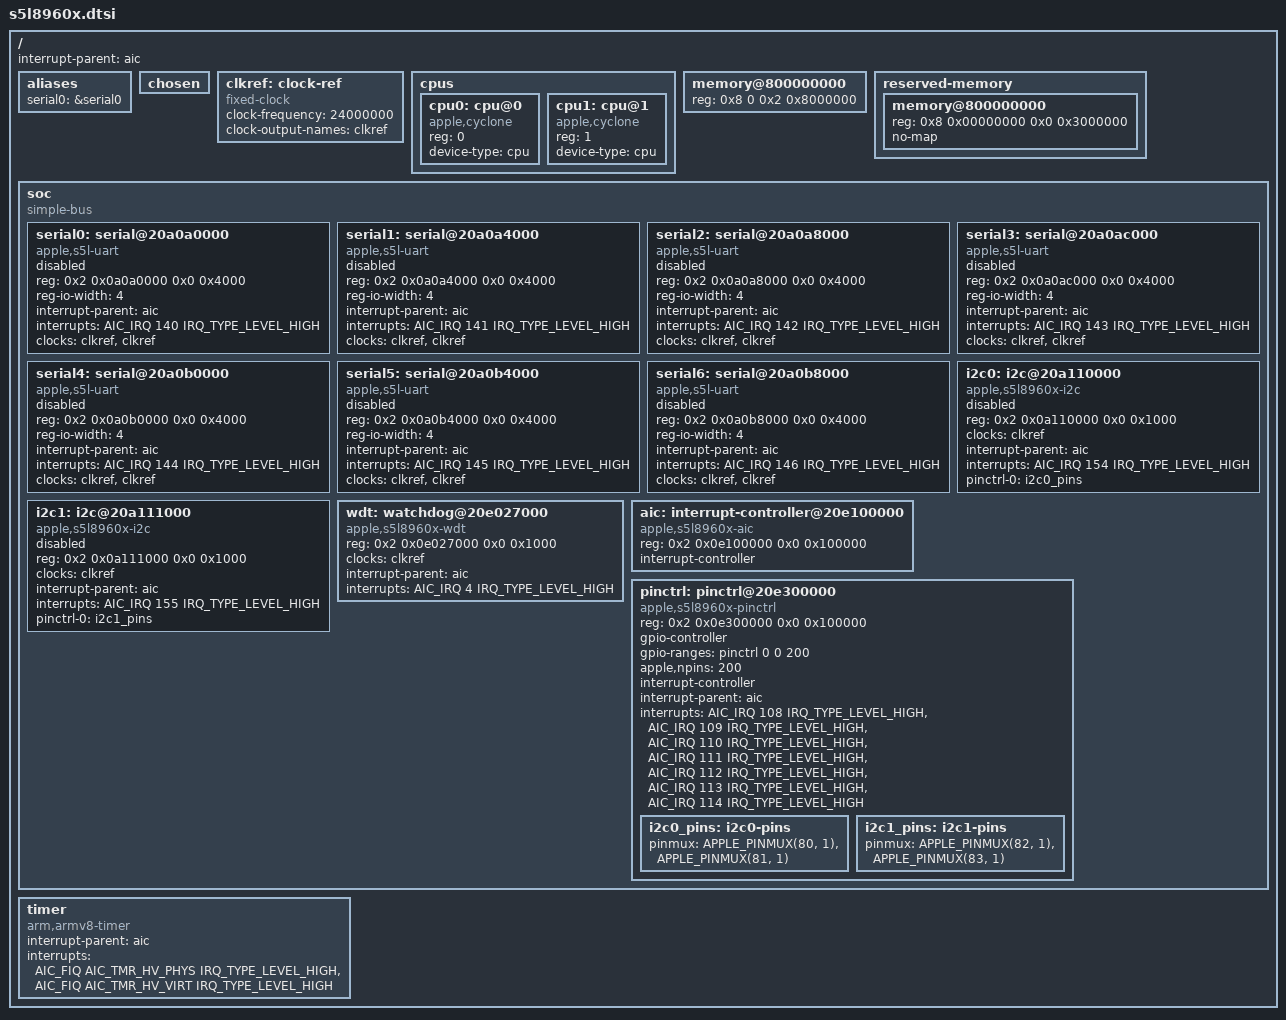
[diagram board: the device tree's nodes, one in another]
// SPDX-License-Identifier: GPL-2.0+ OR MIT
/*
 * Apple S5L8960X "A7" SoC
 *
 * Copyright (c) 2022, Konrad Dybcio <konrad.dybcio@somainline.org>
 * Based on Asahi Linux's M1 (t8103.dtsi) and Corellium's A10 efforts.
 */

#include <dt-bindings/gpio/gpio.h>
#include <dt-bindings/interrupt-controller/apple-aic.h>
#include <dt-bindings/interrupt-controller/irq.h>
#include <dt-bindings/pinctrl/apple.h>

/ {
	interrupt-parent = <&aic>;
	#address-cells = <2>;
	#size-cells = <2>;

	aliases {
		serial0 = &serial0;
	};

	chosen {
		#address-cells = <2>;
		#size-cells = <2>;
		ranges;
	};

	clkref: clock-ref {
		compatible = "fixed-clock";
		#clock-cells = <0>;
		clock-frequency = <24000000>;
		clock-output-names = "clkref";
	};

	cpus {
		#address-cells = <1>;
		#size-cells = <0>;

		cpu0: cpu@0 {
			compatible = "apple,cyclone";
			reg = <0>;
			device-type = "cpu";
		};

		cpu1: cpu@1 {
			compatible = "apple,cyclone";
			reg = <1>;
			device-type = "cpu";
		};
	};

	memory@800000000 {
		device_type = "memory";
		reg = <0x8 0 0x2 0x8000000>; /* To be filled by loader */
	};

	reserved-memory {
		#address-cells = <2>;
		#size-cells = <2>;
		ranges;

		memory@800000000 {
			reg = <0x8 0x00000000 0x0 0x3000000>;
			no-map;
		};
	};

	soc {
		compatible = "simple-bus";
		#address-cells = <2>;
		#size-cells = <2>;
		ranges;

		serial0: serial@20a0a0000 {
			compatible = "apple,s5l-uart";
			reg = <0x2 0x0a0a0000 0x0 0x4000>;
			reg-io-width = <4>;
			interrupt-parent = <&aic>;
			interrupts = <AIC_IRQ 140 IRQ_TYPE_LEVEL_HIGH>;
			/* Use the bootloader-enabled clocks for now. */
			clocks = <&clkref>, <&clkref>;
			clock-names = "uart", "clk_uart_baud0";
			status = "disabled";
		};

		serial1: serial@20a0a4000 {
			compatible = "apple,s5l-uart";
			reg = <0x2 0x0a0a4000 0x0 0x4000>;
			reg-io-width = <4>;
			interrupt-parent = <&aic>;
			interrupts = <AIC_IRQ 141 IRQ_TYPE_LEVEL_HIGH>;
			/* Use the bootloader-enabled clocks for now. */
			clocks = <&clkref>, <&clkref>;
			clock-names = "uart", "clk_uart_baud0";
			status = "disabled";
		};

		serial2: serial@20a0a8000 {
			compatible = "apple,s5l-uart";
			reg = <0x2 0x0a0a8000 0x0 0x4000>;
			reg-io-width = <4>;
			interrupt-parent = <&aic>;
			interrupts = <AIC_IRQ 142 IRQ_TYPE_LEVEL_HIGH>;
			/* Use the bootloader-enabled clocks for now. */
			clocks = <&clkref>, <&clkref>;
			clock-names = "uart", "clk_uart_baud0";
			status = "disabled";
		};

		serial3: serial@20a0ac000 {
			compatible = "apple,s5l-uart";
			reg = <0x2 0x0a0ac000 0x0 0x4000>;
			reg-io-width = <4>;
			interrupt-parent = <&aic>;
			interrupts = <AIC_IRQ 143 IRQ_TYPE_LEVEL_HIGH>;
			/* Use the bootloader-enabled clocks for now. */
			clocks = <&clkref>, <&clkref>;
			clock-names = "uart", "clk_uart_baud0";
			status = "disabled";
		};

		serial4: serial@20a0b0000 {
			compatible = "apple,s5l-uart";
			reg = <0x2 0x0a0b0000 0x0 0x4000>;
			reg-io-width = <4>;
			interrupt-parent = <&aic>;
			interrupts = <AIC_IRQ 144 IRQ_TYPE_LEVEL_HIGH>;
			/* Use the bootloader-enabled clocks for now. */
			clocks = <&clkref>, <&clkref>;
			clock-names = "uart", "clk_uart_baud0";
			status = "disabled";
		};

		serial5: serial@20a0b4000 {
			compatible = "apple,s5l-uart";
			reg = <0x2 0x0a0b4000 0x0 0x4000>;
			reg-io-width = <4>;
			interrupt-parent = <&aic>;
			interrupts = <AIC_IRQ 145 IRQ_TYPE_LEVEL_HIGH>;
			/* Use the bootloader-enabled clocks for now. */
			clocks = <&clkref>, <&clkref>;
			clock-names = "uart", "clk_uart_baud0";
			status = "disabled";
		};

		serial6: serial@20a0b8000 {
			compatible = "apple,s5l-uart";
			reg = <0x2 0x0a0b8000 0x0 0x4000>;
			reg-io-width = <4>;
			interrupt-parent = <&aic>;
			interrupts = <AIC_IRQ 146 IRQ_TYPE_LEVEL_HIGH>;
			/* Use the bootloader-enabled clocks for now. */
			clocks = <&clkref>, <&clkref>;
			clock-names = "uart", "clk_uart_baud0";
			status = "disabled";
		};

		i2c0: i2c@20a110000 {
			compatible = "apple,s5l8960x-i2c", "apple,i2c";
			reg = <0x2 0x0a110000 0x0 0x1000>;
			clocks = <&clkref>;
			interrupt-parent = <&aic>;
			interrupts = <AIC_IRQ 154 IRQ_TYPE_LEVEL_HIGH>;
			pinctrl-0 = <&i2c0_pins>;
			pinctrl-names = "default";
			#address-cells = <1>;
			#size-cells = <0>;
			status = "disabled";
		};

		i2c1: i2c@20a111000 {
			compatible = "apple,s5l8960x-i2c", "apple,i2c";
			reg = <0x2 0x0a111000 0x0 0x1000>;
			clocks = <&clkref>;
			interrupt-parent = <&aic>;
			interrupts = <AIC_IRQ 155 IRQ_TYPE_LEVEL_HIGH>;
			pinctrl-0 = <&i2c1_pins>;
			pinctrl-names = "default";
			#address-cells = <1>;
			#size-cells = <0>;
			status = "disabled";
		};

		wdt: watchdog@20e027000 {
			compatible = "apple,s5l8960x-wdt", "apple,wdt";
			reg = <0x2 0x0e027000 0x0 0x1000>;
			clocks = <&clkref>;
			interrupt-parent = <&aic>;
			interrupts = <AIC_IRQ 4 IRQ_TYPE_LEVEL_HIGH>;
		};

		aic: interrupt-controller@20e100000 {
			compatible = "apple,s5l8960x-aic", "apple,aic";
			reg = <0x2 0x0e100000 0x0 0x100000>;
			#interrupt-cells = <3>;
			interrupt-controller;
		};

		pinctrl: pinctrl@20e300000 {
			compatible = "apple,s5l8960x-pinctrl", "apple,pinctrl";
			reg = <0x2 0x0e300000 0x0 0x100000>;

			gpio-controller;
			#gpio-cells = <2>;
			gpio-ranges = <&pinctrl 0 0 200>;
			apple,npins = <200>;

			interrupt-controller;
			#interrupt-cells = <2>;
			interrupt-parent = <&aic>;
			interrupts = <AIC_IRQ 108 IRQ_TYPE_LEVEL_HIGH>,
				     <AIC_IRQ 109 IRQ_TYPE_LEVEL_HIGH>,
				     <AIC_IRQ 110 IRQ_TYPE_LEVEL_HIGH>,
				     <AIC_IRQ 111 IRQ_TYPE_LEVEL_HIGH>,
				     <AIC_IRQ 112 IRQ_TYPE_LEVEL_HIGH>,
				     <AIC_IRQ 113 IRQ_TYPE_LEVEL_HIGH>,
				     <AIC_IRQ 114 IRQ_TYPE_LEVEL_HIGH>;

			i2c0_pins: i2c0-pins {
				pinmux = <APPLE_PINMUX(80, 1)>, <APPLE_PINMUX(81, 1)>;
			};

			i2c1_pins: i2c1-pins {
				pinmux = <APPLE_PINMUX(82, 1)>, <APPLE_PINMUX(83, 1)>;
			};
		};
	};

	timer {
		compatible = "arm,armv8-timer";
		interrupt-parent = <&aic>;
		interrupt-names = "phys", "virt";
		/* Note that A7 doesn't actually have a hypervisor (EL2 is not implemented). */
		interrupts = <AIC_FIQ AIC_TMR_HV_PHYS IRQ_TYPE_LEVEL_HIGH>,
			     <AIC_FIQ AIC_TMR_HV_VIRT IRQ_TYPE_LEVEL_HIGH>;
	};
};
